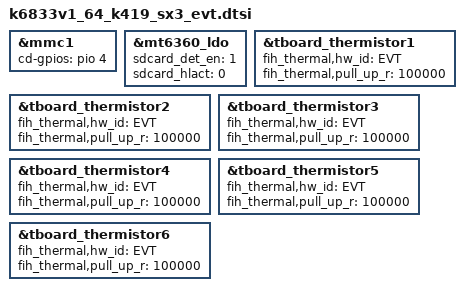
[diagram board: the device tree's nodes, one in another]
/* OVERLAY,SX3,EVT */
#include "overlay_sx3_evt_fih_info.dtsi"
#include "overlay_sx3_pre_evt_fih_fp.dtsi"
#include <dt-bindings/gpio/gpio.h>


/* SD card insert detect high active change */
&mmc1 {
	cd-gpios = <&pio 4 GPIO_ACTIVE_HIGH>;
};

&mt6360_ldo {
	sdcard_det_en = <1>;
	sdcard_hlact = <0>;
};

&tboard_thermistor1 {
	fih_thermal,hw_id = "EVT";
	fih_thermal,pull_up_r = <100000>;
};

&tboard_thermistor2 {
	fih_thermal,hw_id = "EVT";
	fih_thermal,pull_up_r = <100000>;
};

&tboard_thermistor3 {
	fih_thermal,hw_id = "EVT";
	fih_thermal,pull_up_r = <100000>;
};

&tboard_thermistor4 {
	fih_thermal,hw_id = "EVT";
	fih_thermal,pull_up_r = <100000>;
};
&tboard_thermistor5 {
	fih_thermal,hw_id = "EVT";
	fih_thermal,pull_up_r = <100000>;
};

&tboard_thermistor6 {
	fih_thermal,hw_id = "EVT";
	fih_thermal,pull_up_r = <100000>;
};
